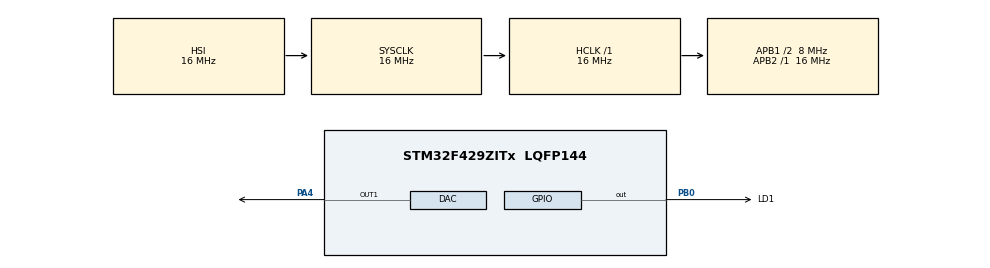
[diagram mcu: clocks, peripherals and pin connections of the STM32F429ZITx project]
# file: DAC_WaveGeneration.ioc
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DAC.DAC_Trigger=DAC_TRIGGER_T2_TRGO
Dma.DAC1.0.Direction=DMA_MEMORY_TO_PERIPH
Dma.DAC1.0.FIFOMode=DMA_FIFOMODE_DISABLE
Dma.DAC1.0.Instance=DMA1_Stream5
Dma.DAC1.0.MemDataAlignment=DMA_MDATAALIGN_HALFWORD
Dma.DAC1.0.MemInc=DMA_MINC_ENABLE
Dma.DAC1.0.Mode=DMA_CIRCULAR
Dma.DAC1.0.PeriphDataAlignment=DMA_PDATAALIGN_HALFWORD
Dma.DAC1.0.PeriphInc=DMA_PINC_DISABLE
Dma.DAC1.0.Priority=DMA_PRIORITY_HIGH
Dma.Request0=DAC1
Mcu.Family=STM32F4
Mcu.Name=STM32F429ZITx
Mcu.Package=LQFP144
NVIC.DMA1_Stream5_IRQn=true\:0\:0\:false\:false\:true\:false\:true\:true
NVIC.PriorityGroup=NVIC_PRIORITYGROUP_4
PA13.Mode=Serial_Wire
PA13.Signal=SYS_JTMS-SWDIO
PA14.Mode=Serial_Wire
PA14.Signal=SYS_JTCK-SWCLK
PA4.Signal=COMP_DAC1_group
PB0.GPIO_Label=LD1
PB0.Signal=GPIO_Output
PC14/OSC32_IN.Mode=LSE-External-Oscillator
PC14/OSC32_IN.Signal=RCC_OSC32_IN
PC15/OSC32_OUT.Mode=LSE-External-Oscillator
PC15/OSC32_OUT.Signal=RCC_OSC32_OUT
PH0/OSC_IN.Mode=HSE-External-Oscillator
PH0/OSC_IN.Signal=RCC_OSC_IN
PH1/OSC_OUT.Mode=HSE-External-Oscillator
PH1/OSC_OUT.Signal=RCC_OSC_OUT
ProjectManager.HeapSize=0x200
ProjectManager.StackSize=0x400
ProjectManager.TargetToolchain=CMake
RCC.48MHZClocksFreq_Value=48000000
RCC.AHBFreq_Value=16000000
RCC.APB1CLKDivider=RCC_HCLK_DIV2
RCC.APB1Freq_Value=8000000
RCC.APB1TimFreq_Value=16000000
RCC.APB2Freq_Value=16000000
RCC.APB2TimFreq_Value=16000000
RCC.CortexFreq_Value=16000000
RCC.HCLKFreq_Value=16000000
RCC.HSE_VALUE=8000000
RCC.HSI_VALUE=16000000
RCC.PLLMUL=RCC_PLL_MUL9
RCC.PRESCALERUSB=RCC_USBCLKSOURCE_PLL_DIV1_5
RCC.SYSCLKFreq_VALUE=16000000
RCC.SYSCLKSourceVirtual=RCC_SYSCLKSOURCE_PLLCLK
RCC.USBFreq_Value=48000000
RCC.VCOOutputFreq_Value=192000000
SH.COMP_DAC1_group.0=DAC_OUT1,DAC_OUT1
TIM2.Period=24
TIM2.Prescaler=15
TIM2.TIM_MasterOutputTrigger=TIM_TRGO_UPDATE
VP_TIM2_VS_ClockSourceINT.Mode=Internal
board=NUCLEO-F429ZI

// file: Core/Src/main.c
/* USER CODE BEGIN Header */
/**
  ******************************************************************************
  * @file           : main.c
  * @brief          : Main program body
  ******************************************************************************
  * @attention
  *
  * Copyright (c) 2024 STMicroelectronics.
  * All rights reserved.
  *
  * This software is licensed under terms that can be found in the LICENSE file
  * in the root directory of this software component.
  * If no LICENSE file comes with this software, it is provided AS-IS.
  *
  ******************************************************************************
  */
/* USER CODE END Header */
#include "main.h"
#include "dac.h"
#include "dma.h"
#include "tim.h"
#include "gpio.h"

/* USER CODE BEGIN Includes */
#include <math.h>
/* USER CODE END Includes */

/* USER CODE BEGIN PD */
#define SAMPLING_RATE 100000
#define SINE_FREQUENCY 500
#define AMPLITUDE 0.5 // volts in the range of [0, 1.65]
#define DAC_BUFFER_SIZE (SAMPLING_RATE/SINE_FREQUENCY) // Do not modify
#define PRESCALED_FREQUENCY 1000000 // frequency of TIM2 / (PSC + 1)
/* USER CODE END PD */

/* USER CODE BEGIN PV */
uint16_t dacBuffer[DAC_BUFFER_SIZE] = {0};
/* USER CODE END PV */

void SystemClock_Config(void);

int main(void)
{

  /* USER CODE BEGIN 1 */
  /* Generate sine wave DAC data */
  for (size_t i = 0; i < DAC_BUFFER_SIZE; i++)
  {
    dacBuffer[i] = (uint16_t)((AMPLITUDE*sinf(2*M_PI*SINE_FREQUENCY*i/SAMPLING_RATE)+AMPLITUDE) * 4096 / 3.3);
  }
  /* USER CODE END 1 */

  /* MCU Configuration--------------------------------------------------------*/

  /* Reset of all peripherals, Initializes the Flash interface and the Systick. */
  HAL_Init();

  /* Configure the system clock */
  SystemClock_Config();

  /* Initialize all configured peripherals */
  MX_GPIO_Init();
  MX_DMA_Init();
  MX_DAC_Init();
  MX_TIM2_Init();
  /* USER CODE BEGIN 2 */
  // Adjust timer period (ARR)
  htim2.Init.Period = PRESCALED_FREQUENCY / DAC_BUFFER_SIZE / SINE_FREQUENCY - 1;
  HAL_TIM_Base_Init(&htim2);
  HAL_TIM_Base_Start(&htim2);
  HAL_DAC_Start_DMA(&hdac, DAC_CHANNEL_1, (uint32_t *)dacBuffer, DAC_BUFFER_SIZE, DAC_ALIGN_12B_R);
  /* USER CODE END 2 */

  /* Infinite loop */
  while (1)
  {

  }
}

void SystemClock_Config(void)
{
  RCC_OscInitTypeDef RCC_OscInitStruct = {0};
  RCC_ClkInitTypeDef RCC_ClkInitStruct = {0};

  /** Configure the main internal regulator output voltage
  */
  __HAL_RCC_PWR_CLK_ENABLE();
  __HAL_PWR_VOLTAGESCALING_CONFIG(PWR_REGULATOR_VOLTAGE_SCALE3);

  /** Initializes the RCC Oscillators according to the specified parameters
  * in the RCC_OscInitTypeDef structure.
  */
  RCC_OscInitStruct.OscillatorType = RCC_OSCILLATORTYPE_HSI;
  RCC_OscInitStruct.HSIState = RCC_HSI_ON;
  RCC_OscInitStruct.HSICalibrationValue = RCC_HSICALIBRATION_DEFAULT;
  RCC_OscInitStruct.PLL.PLLState = RCC_PLL_NONE;
  if (HAL_RCC_OscConfig(&RCC_OscInitStruct) != HAL_OK)
  {
    Error_Handler();
  }

  /** Initializes the CPU, AHB and APB buses clocks
  */
  RCC_ClkInitStruct.ClockType = RCC_CLOCKTYPE_HCLK|RCC_CLOCKTYPE_SYSCLK
                              |RCC_CLOCKTYPE_PCLK1|RCC_CLOCKTYPE_PCLK2;
  RCC_ClkInitStruct.SYSCLKSource = RCC_SYSCLKSOURCE_HSI;
  RCC_ClkInitStruct.AHBCLKDivider = RCC_SYSCLK_DIV1;
  RCC_ClkInitStruct.APB1CLKDivider = RCC_HCLK_DIV2;
  RCC_ClkInitStruct.APB2CLKDivider = RCC_HCLK_DIV1;

  if (HAL_RCC_ClockConfig(&RCC_ClkInitStruct, FLASH_LATENCY_0) != HAL_OK)
  {
    Error_Handler();
  }
}

void Error_Handler(void)
{
  __disable_irq();
  while (1)
  {
  }
}
